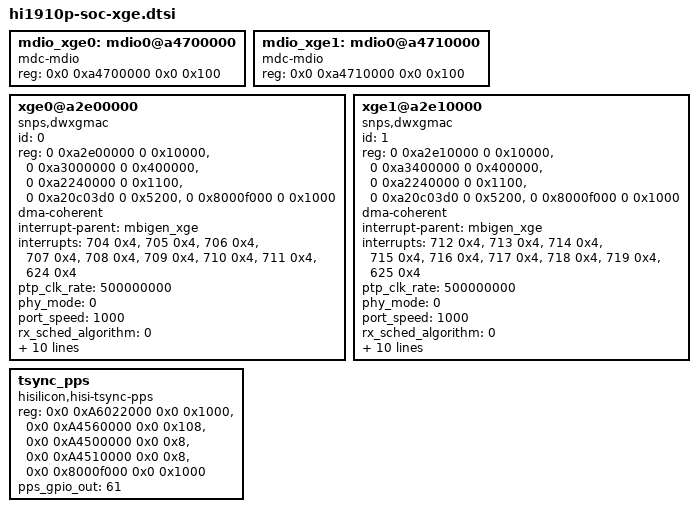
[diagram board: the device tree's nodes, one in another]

    mdio_xge0: mdio0@a4700000 {
        compatible = "mdc-mdio";
        reg = <0x0 0xa4700000 0x0 0x100>;
        #address-cells = <0x1>;
        #size-cells = <0x0>;
    };

    mdio_xge1: mdio0@a4710000 {
        compatible = "mdc-mdio";
        reg = <0x0 0xa4710000 0x0 0x100>;
        #address-cells = <0x1>;
        #size-cells = <0x0>;
    };

    xge0@a2e00000 {
        compatible = "snps,dwxgmac";
        id = <0>;
        reg = <0 0xa2e00000 0 0x10000>,
              <0 0xa3000000 0 0x400000>,
              <0 0xa2240000 0 0x1100>,
              <0 0xa20c03d0 0 0x5200>,
              <0 0x8000f000 0 0x1000>;
        reg-names = "xgmac-port", "xgmac-common", "xgmac-top", "io subctrl", "sysctrl";
        dma-coherent;
        interrupt-parent = <&mbigen_xge>;
        interrupts = <704 0x4>,
                     <705 0x4>,
                     <706 0x4>,
                     <707 0x4>,
                     <708 0x4>,
                     <709 0x4>,
                     <710 0x4>,
                     <711 0x4>,
                     <624 0x4>;
        interrupt-names = "queue0-irq", "queue1-irq", "queue2-irq", "queue3-irq",
                          "queue4-irq", "queue5-irq", "queue6-irq", "queue7-irq",
                          "func_irq";
        ptp_clk_rate = <500000000>;
        phy_mode = <0>;
        port_speed = <1000>;
        rx_sched_algorithm = <0>;
        tx_sched_algorithm = <0>;
        rss_en = <0>;
        drop_err_pkt = <0>;
        ring_size = <1024>;
        auto_negotiation = <0>;
        an_role = <0>;
        queue_num = <4>;
        rxq_weight = <1 1 1 1>;
        tx_vlan_pri_map = <0 0 0 0 0 0 0 0>;
        tsn_ptp_tx_skb_queue = <3>;
    };

    xge1@a2e10000 {
        compatible = "snps,dwxgmac";
        id = <1>;
        reg = <0 0xa2e10000 0 0x10000>,
              <0 0xa3400000 0 0x400000>,
              <0 0xa2240000 0 0x1100>,
              <0 0xa20c03d0 0 0x5200>,
              <0 0x8000f000 0 0x1000>;
        reg-names = "xgmac-port", "xgmac-common", "xgmac-top", "io subctrl", "sysctrl";
        dma-coherent;
        interrupt-parent = <&mbigen_xge>;
        interrupts = <712 0x4>,
                     <713 0x4>,
                     <714 0x4>,
                     <715 0x4>,
                     <716 0x4>,
                     <717 0x4>,
                     <718 0x4>,
                     <719 0x4>,
                     <625 0x4>;
        interrupt-names = "queue0-irq", "queue1-irq", "queue2-irq", "queue3-irq",
                          "queue4-irq", "queue5-irq", "queue6-irq", "queue7-irq",
                          "func_irq";

        ptp_clk_rate = <500000000>;
        phy_mode = <0>;
        port_speed = <1000>;
        rx_sched_algorithm = <0>;
        tx_sched_algorithm = <0>;
        rss_en = <0>;
        drop_err_pkt = <0>;
        ring_size = <1024>;
        auto_negotiation = <0>;
        an_role = <0>;
        queue_num = <8>;
        rxq_weight = <1 1 1 1 1 1 1 1>;
        tx_vlan_pri_map = <0 0 0 0 0 0 0 0>;
        tsn_ptp_tx_skb_queue = <7>;
    };

    tsync_pps {
        compatible = "hisilicon,hisi-tsync-pps";
        reg = <0x0 0xA6022000 0x0 0x1000>,
              <0x0 0xA4560000 0x0 0x108>,
              <0x0 0xA4500000 0x0 0x8>,
              <0x0 0xA4510000 0x0 0x8>,
              <0x0 0x8000f000 0x0 0x1000>;
        reg-names = "sensorhub-reg","gpio-reg","gpio0-ctrl","gpio61-ctrl","sysctrl";
        pps_gpio_out = <61>;
    };

